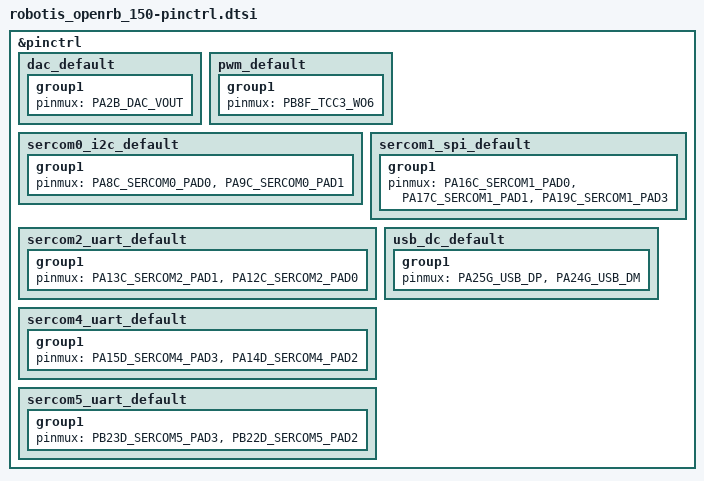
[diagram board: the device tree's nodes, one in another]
/*
 * Copyright (c) 2024 Richard Osterloh <richard.osterloh@gmail.com>
 *
 * SPDX-License-Identifier: Apache-2.0
 */

#include <dt-bindings/pinctrl/samd21-da1gXabcd-pinctrl.h>

&pinctrl {
	dac_default: dac_default {
		group1 {
			pinmux = <PA2B_DAC_VOUT>;
		};
	};

	pwm_default: pwm_default {
		group1 {
			pinmux = <PB8F_TCC3_WO6>;
		};
	};

	sercom0_i2c_default: sercom0_i2c_default {
		group1 {
			pinmux = <PA8C_SERCOM0_PAD0>,
				 <PA9C_SERCOM0_PAD1>;
		};
	};
	sercom1_spi_default: sercom1_spi_default {
		group1 {
			pinmux = <PA16C_SERCOM1_PAD0>,
				 <PA17C_SERCOM1_PAD1>,
				 <PA19C_SERCOM1_PAD3>;
		};
	};
	sercom2_uart_default: sercom2_uart_default {
		group1 {
			pinmux = <PA13C_SERCOM2_PAD1>,
				 <PA12C_SERCOM2_PAD0>;
		};
	};
	sercom4_uart_default: sercom4_uart_default {
		group1 {
			pinmux = <PA15D_SERCOM4_PAD3>,
				 <PA14D_SERCOM4_PAD2>;
		};
	};
	sercom5_uart_default: sercom5_uart_default {
		group1 {
			pinmux = <PB23D_SERCOM5_PAD3>,
				 <PB22D_SERCOM5_PAD2>;
		};
	};

	usb_dc_default: usb_dc_default {
		group1 {
			pinmux = <PA25G_USB_DP>,
				 <PA24G_USB_DM>;
		};
	};
};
